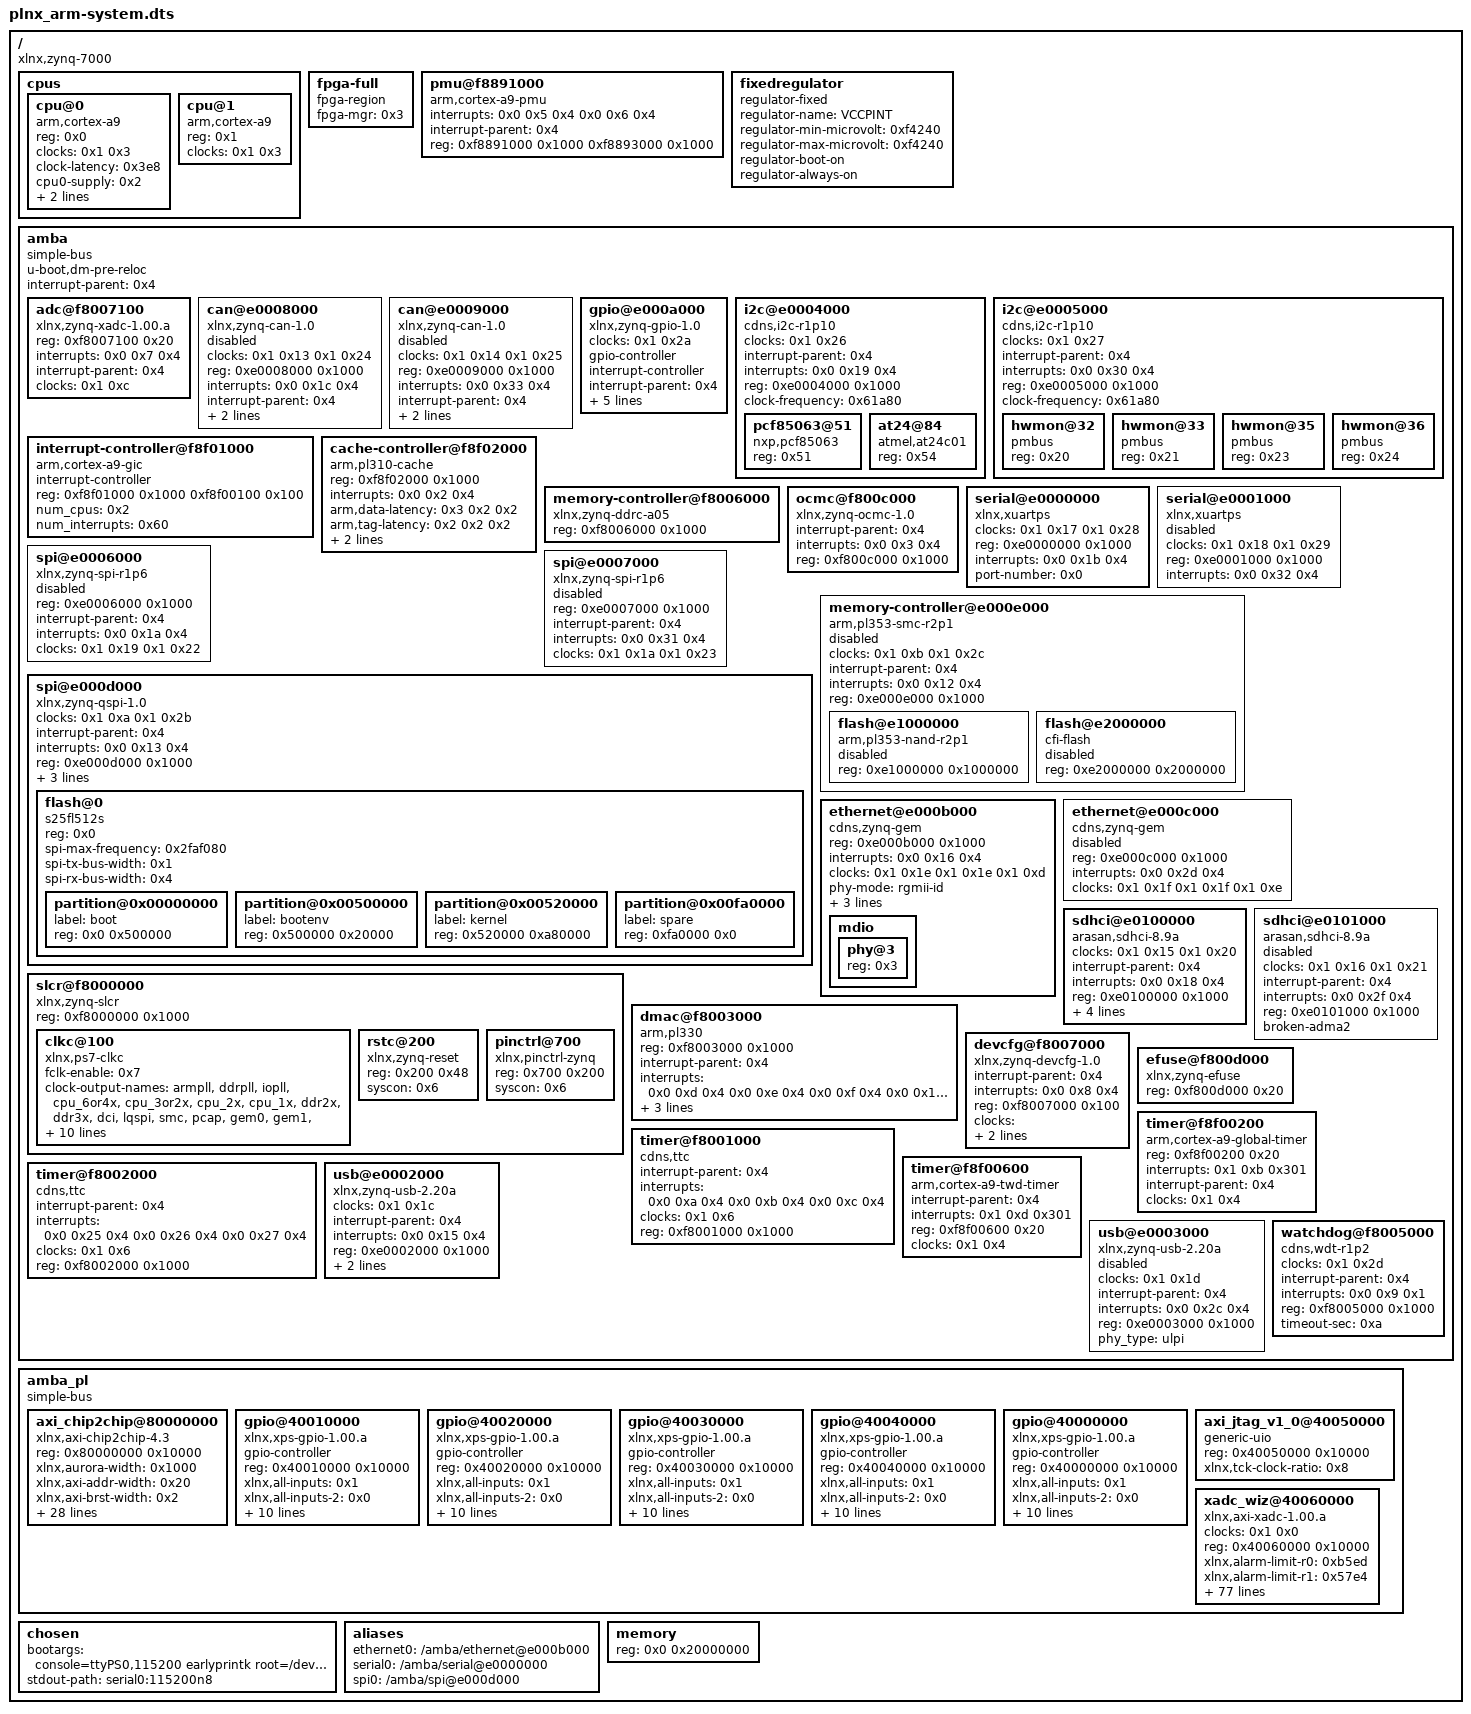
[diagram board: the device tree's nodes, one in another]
/dts-v1/;

/ {
	#address-cells = <0x1>;
	#size-cells = <0x1>;
	compatible = "xlnx,zynq-7000";

	cpus {
		#address-cells = <0x1>;
		#size-cells = <0x0>;

		cpu@0 {
			compatible = "arm,cortex-a9";
			device_type = "cpu";
			reg = <0x0>;
			clocks = <0x1 0x3>;
			clock-latency = <0x3e8>;
			cpu0-supply = <0x2>;
			operating-points = <0xa2c2a 0xf4240 0x51615 0xf4240>;
		};

		cpu@1 {
			compatible = "arm,cortex-a9";
			device_type = "cpu";
			reg = <0x1>;
			clocks = <0x1 0x3>;
		};
	};

	fpga-full {
		compatible = "fpga-region";
		fpga-mgr = <0x3>;
		#address-cells = <0x1>;
		#size-cells = <0x1>;
		ranges;
	};

	pmu@f8891000 {
		compatible = "arm,cortex-a9-pmu";
		interrupts = <0x0 0x5 0x4 0x0 0x6 0x4>;
		interrupt-parent = <0x4>;
		reg = <0xf8891000 0x1000 0xf8893000 0x1000>;
	};

	fixedregulator {
		compatible = "regulator-fixed";
		regulator-name = "VCCPINT";
		regulator-min-microvolt = <0xf4240>;
		regulator-max-microvolt = <0xf4240>;
		regulator-boot-on;
		regulator-always-on;
		linux,phandle = <0x2>;
		phandle = <0x2>;
	};

	amba {
		u-boot,dm-pre-reloc;
		compatible = "simple-bus";
		#address-cells = <0x1>;
		#size-cells = <0x1>;
		interrupt-parent = <0x4>;
		ranges;

		adc@f8007100 {
			compatible = "xlnx,zynq-xadc-1.00.a";
			reg = <0xf8007100 0x20>;
			interrupts = <0x0 0x7 0x4>;
			interrupt-parent = <0x4>;
			clocks = <0x1 0xc>;
		};

		can@e0008000 {
			compatible = "xlnx,zynq-can-1.0";
			status = "disabled";
			clocks = <0x1 0x13 0x1 0x24>;
			clock-names = "can_clk", "pclk";
			reg = <0xe0008000 0x1000>;
			interrupts = <0x0 0x1c 0x4>;
			interrupt-parent = <0x4>;
			tx-fifo-depth = <0x40>;
			rx-fifo-depth = <0x40>;
		};

		can@e0009000 {
			compatible = "xlnx,zynq-can-1.0";
			status = "disabled";
			clocks = <0x1 0x14 0x1 0x25>;
			clock-names = "can_clk", "pclk";
			reg = <0xe0009000 0x1000>;
			interrupts = <0x0 0x33 0x4>;
			interrupt-parent = <0x4>;
			tx-fifo-depth = <0x40>;
			rx-fifo-depth = <0x40>;
		};

		gpio@e000a000 {
			compatible = "xlnx,zynq-gpio-1.0";
			#gpio-cells = <0x2>;
			clocks = <0x1 0x2a>;
			gpio-controller;
			interrupt-controller;
			#interrupt-cells = <0x2>;
			interrupt-parent = <0x4>;
			interrupts = <0x0 0x14 0x4>;
			reg = <0xe000a000 0x1000>;
			emio-gpio-width = <0x40>;
			gpio-mask-high = <0x0>;
			gpio-mask-low = <0x5600>;
		};

		i2c@e0004000 {
			compatible = "cdns,i2c-r1p10";
			status = "okay";
			clocks = <0x1 0x26>;
			interrupt-parent = <0x4>;
			interrupts = <0x0 0x19 0x4>;
			reg = <0xe0004000 0x1000>;
			#address-cells = <0x1>;
			#size-cells = <0x0>;
			clock-frequency = <0x61a80>;

			pcf85063@51 {
				status = "okay";
				compatible = "nxp,pcf85063";
				reg = <0x51>;
			};

			at24@84 {
				status = "okay";
				compatible = "atmel,at24c01";
				reg = <0x54>;
			};
		};

		i2c@e0005000 {
			compatible = "cdns,i2c-r1p10";
			status = "okay";
			clocks = <0x1 0x27>;
			interrupt-parent = <0x4>;
			interrupts = <0x0 0x30 0x4>;
			reg = <0xe0005000 0x1000>;
			#address-cells = <0x1>;
			#size-cells = <0x0>;
			clock-frequency = <0x61a80>;

			hwmon@32 {
				status = "okay";
				compatible = "pmbus";
				reg = <0x20>;
			};

			hwmon@33 {
				status = "okay";
				compatible = "pmbus";
				reg = <0x21>;
			};

			hwmon@35 {
				status = "okay";
				compatible = "pmbus";
				reg = <0x23>;
			};

			hwmon@36 {
				status = "okay";
				compatible = "pmbus";
				reg = <0x24>;
			};
		};

		interrupt-controller@f8f01000 {
			compatible = "arm,cortex-a9-gic";
			#interrupt-cells = <0x3>;
			interrupt-controller;
			reg = <0xf8f01000 0x1000 0xf8f00100 0x100>;
			num_cpus = <0x2>;
			num_interrupts = <0x60>;
			linux,phandle = <0x4>;
			phandle = <0x4>;
		};

		cache-controller@f8f02000 {
			compatible = "arm,pl310-cache";
			reg = <0xf8f02000 0x1000>;
			interrupts = <0x0 0x2 0x4>;
			arm,data-latency = <0x3 0x2 0x2>;
			arm,tag-latency = <0x2 0x2 0x2>;
			cache-unified;
			cache-level = <0x2>;
		};

		memory-controller@f8006000 {
			compatible = "xlnx,zynq-ddrc-a05";
			reg = <0xf8006000 0x1000>;
		};

		ocmc@f800c000 {
			compatible = "xlnx,zynq-ocmc-1.0";
			interrupt-parent = <0x4>;
			interrupts = <0x0 0x3 0x4>;
			reg = <0xf800c000 0x1000>;
		};

		serial@e0000000 {
			compatible = "xlnx,xuartps", "cdns,uart-r1p8";
			status = "okay";
			clocks = <0x1 0x17 0x1 0x28>;
			clock-names = "uart_clk", "pclk";
			reg = <0xe0000000 0x1000>;
			interrupts = <0x0 0x1b 0x4>;
			device_type = "serial";
			port-number = <0x0>;
		};

		serial@e0001000 {
			compatible = "xlnx,xuartps", "cdns,uart-r1p8";
			status = "disabled";
			clocks = <0x1 0x18 0x1 0x29>;
			clock-names = "uart_clk", "pclk";
			reg = <0xe0001000 0x1000>;
			interrupts = <0x0 0x32 0x4>;
		};

		spi@e0006000 {
			compatible = "xlnx,zynq-spi-r1p6";
			reg = <0xe0006000 0x1000>;
			status = "disabled";
			interrupt-parent = <0x4>;
			interrupts = <0x0 0x1a 0x4>;
			clocks = <0x1 0x19 0x1 0x22>;
			clock-names = "ref_clk", "pclk";
			#address-cells = <0x1>;
			#size-cells = <0x0>;
		};

		spi@e0007000 {
			compatible = "xlnx,zynq-spi-r1p6";
			reg = <0xe0007000 0x1000>;
			status = "disabled";
			interrupt-parent = <0x4>;
			interrupts = <0x0 0x31 0x4>;
			clocks = <0x1 0x1a 0x1 0x23>;
			clock-names = "ref_clk", "pclk";
			#address-cells = <0x1>;
			#size-cells = <0x0>;
		};

		spi@e000d000 {
			clock-names = "ref_clk", "pclk";
			clocks = <0x1 0xa 0x1 0x2b>;
			compatible = "xlnx,zynq-qspi-1.0";
			status = "okay";
			interrupt-parent = <0x4>;
			interrupts = <0x0 0x13 0x4>;
			reg = <0xe000d000 0x1000>;
			#address-cells = <0x1>;
			#size-cells = <0x0>;
			is-dual = <0x0>;
			num-cs = <0x1>;
			u-boot,dm-pre-reloc;

			flash@0 {
				compatible = "s25fl512s";
				reg = <0x0>;
				#address-cells = <0x1>;
				#size-cells = <0x1>;
				spi-max-frequency = <0x2faf080>;
				spi-tx-bus-width = <0x1>;
				spi-rx-bus-width = <0x4>;

				partition@0x00000000 {
					label = "boot";
					reg = <0x0 0x500000>;
				};

				partition@0x00500000 {
					label = "bootenv";
					reg = <0x500000 0x20000>;
				};

				partition@0x00520000 {
					label = "kernel";
					reg = <0x520000 0xa80000>;
				};

				partition@0x00fa0000 {
					label = "spare";
					reg = <0xfa0000 0x0>;
				};
			};
		};

		memory-controller@e000e000 {
			#address-cells = <0x1>;
			#size-cells = <0x1>;
			status = "disabled";
			clock-names = "memclk", "aclk";
			clocks = <0x1 0xb 0x1 0x2c>;
			compatible = "arm,pl353-smc-r2p1";
			interrupt-parent = <0x4>;
			interrupts = <0x0 0x12 0x4>;
			ranges;
			reg = <0xe000e000 0x1000>;

			flash@e1000000 {
				status = "disabled";
				compatible = "arm,pl353-nand-r2p1";
				reg = <0xe1000000 0x1000000>;
				#address-cells = <0x1>;
				#size-cells = <0x1>;
			};

			flash@e2000000 {
				status = "disabled";
				compatible = "cfi-flash";
				reg = <0xe2000000 0x2000000>;
				#address-cells = <0x1>;
				#size-cells = <0x1>;
			};
		};

		ethernet@e000b000 {
			compatible = "cdns,zynq-gem", "cdns,gem";
			reg = <0xe000b000 0x1000>;
			status = "okay";
			interrupts = <0x0 0x16 0x4>;
			clocks = <0x1 0x1e 0x1 0x1e 0x1 0xd>;
			clock-names = "pclk", "hclk", "tx_clk";
			#address-cells = <0x1>;
			#size-cells = <0x0>;
			phy-mode = "rgmii-id";
			xlnx,ptp-enet-clock = <0x69f6bcb>;
			local-mac-address = [00 0a 35 00 1e 53];
			phy-handle = <0x5>;

			mdio {

				phy@3 {
					device_type = "ethernet-phy";
					reg = <0x3>;
					linux,phandle = <0x5>;
					phandle = <0x5>;
				};
			};
		};

		ethernet@e000c000 {
			compatible = "cdns,zynq-gem", "cdns,gem";
			reg = <0xe000c000 0x1000>;
			status = "disabled";
			interrupts = <0x0 0x2d 0x4>;
			clocks = <0x1 0x1f 0x1 0x1f 0x1 0xe>;
			clock-names = "pclk", "hclk", "tx_clk";
			#address-cells = <0x1>;
			#size-cells = <0x0>;
		};

		sdhci@e0100000 {
			compatible = "arasan,sdhci-8.9a";
			status = "okay";
			clock-names = "clk_xin", "clk_ahb";
			clocks = <0x1 0x15 0x1 0x20>;
			interrupt-parent = <0x4>;
			interrupts = <0x0 0x18 0x4>;
			reg = <0xe0100000 0x1000>;
			broken-adma2;
			xlnx,has-cd = <0x1>;
			xlnx,has-power = <0x0>;
			xlnx,has-wp = <0x0>;
		};

		sdhci@e0101000 {
			compatible = "arasan,sdhci-8.9a";
			status = "disabled";
			clock-names = "clk_xin", "clk_ahb";
			clocks = <0x1 0x16 0x1 0x21>;
			interrupt-parent = <0x4>;
			interrupts = <0x0 0x2f 0x4>;
			reg = <0xe0101000 0x1000>;
			broken-adma2;
		};

		slcr@f8000000 {
			#address-cells = <0x1>;
			#size-cells = <0x1>;
			compatible = "xlnx,zynq-slcr", "syscon", "simple-mfd";
			reg = <0xf8000000 0x1000>;
			ranges;
			linux,phandle = <0x6>;
			phandle = <0x6>;

			clkc@100 {
				#clock-cells = <0x1>;
				compatible = "xlnx,ps7-clkc";
				fclk-enable = <0x7>;
				clock-output-names = "armpll", "ddrpll", "iopll", "cpu_6or4x", "cpu_3or2x", "cpu_2x", "cpu_1x", "ddr2x", "ddr3x", "dci", "lqspi", "smc", "pcap", "gem0", "gem1", "fclk0", "fclk1", "fclk2", "fclk3", "can0", "can1", "sdio0", "sdio1", "uart0", "uart1", "spi0", "spi1", "dma", "usb0_aper", "usb1_aper", "gem0_aper", "gem1_aper", "sdio0_aper", "sdio1_aper", "spi0_aper", "spi1_aper", "can0_aper", "can1_aper", "i2c0_aper", "i2c1_aper", "uart0_aper", "uart1_aper", "gpio_aper", "lqspi_aper", "smc_aper", "swdt", "dbg_trc", "dbg_apb";
				reg = <0x100 0x100>;
				ps-clk-frequency = <0x1fca055>;
				linux,phandle = <0x1>;
				phandle = <0x1>;
			};

			rstc@200 {
				compatible = "xlnx,zynq-reset";
				reg = <0x200 0x48>;
				#reset-cells = <0x1>;
				syscon = <0x6>;
			};

			pinctrl@700 {
				compatible = "xlnx,pinctrl-zynq";
				reg = <0x700 0x200>;
				syscon = <0x6>;
			};
		};

		dmac@f8003000 {
			compatible = "arm,pl330", "arm,primecell";
			reg = <0xf8003000 0x1000>;
			interrupt-parent = <0x4>;
			interrupt-names = "abort", "dma0", "dma1", "dma2", "dma3", "dma4", "dma5", "dma6", "dma7";
			interrupts = <0x0 0xd 0x4 0x0 0xe 0x4 0x0 0xf 0x4 0x0 0x10 0x4 0x0 0x11 0x4 0x0 0x28 0x4 0x0 0x29 0x4 0x0 0x2a 0x4 0x0 0x2b 0x4>;
			#dma-cells = <0x1>;
			#dma-channels = <0x8>;
			#dma-requests = <0x4>;
			clocks = <0x1 0x1b>;
			clock-names = "apb_pclk";
		};

		devcfg@f8007000 {
			compatible = "xlnx,zynq-devcfg-1.0";
			interrupt-parent = <0x4>;
			interrupts = <0x0 0x8 0x4>;
			reg = <0xf8007000 0x100>;
			clocks = <0x1 0xc 0x1 0xf 0x1 0x10 0x1 0x11 0x1 0x12>;
			clock-names = "ref_clk", "fclk0", "fclk1", "fclk2", "fclk3";
			syscon = <0x6>;
			linux,phandle = <0x3>;
			phandle = <0x3>;
		};

		efuse@f800d000 {
			compatible = "xlnx,zynq-efuse";
			reg = <0xf800d000 0x20>;
		};

		timer@f8f00200 {
			compatible = "arm,cortex-a9-global-timer";
			reg = <0xf8f00200 0x20>;
			interrupts = <0x1 0xb 0x301>;
			interrupt-parent = <0x4>;
			clocks = <0x1 0x4>;
		};

		timer@f8001000 {
			interrupt-parent = <0x4>;
			interrupts = <0x0 0xa 0x4 0x0 0xb 0x4 0x0 0xc 0x4>;
			compatible = "cdns,ttc";
			clocks = <0x1 0x6>;
			reg = <0xf8001000 0x1000>;
		};

		timer@f8002000 {
			interrupt-parent = <0x4>;
			interrupts = <0x0 0x25 0x4 0x0 0x26 0x4 0x0 0x27 0x4>;
			compatible = "cdns,ttc";
			clocks = <0x1 0x6>;
			reg = <0xf8002000 0x1000>;
		};

		timer@f8f00600 {
			interrupt-parent = <0x4>;
			interrupts = <0x1 0xd 0x301>;
			compatible = "arm,cortex-a9-twd-timer";
			reg = <0xf8f00600 0x20>;
			clocks = <0x1 0x4>;
		};

		usb@e0002000 {
			compatible = "xlnx,zynq-usb-2.20a", "chipidea,usb2";
			status = "okay";
			clocks = <0x1 0x1c>;
			interrupt-parent = <0x4>;
			interrupts = <0x0 0x15 0x4>;
			reg = <0xe0002000 0x1000>;
			phy_type = "ulpi";
			dr_mode = "host";
		};

		usb@e0003000 {
			compatible = "xlnx,zynq-usb-2.20a", "chipidea,usb2";
			status = "disabled";
			clocks = <0x1 0x1d>;
			interrupt-parent = <0x4>;
			interrupts = <0x0 0x2c 0x4>;
			reg = <0xe0003000 0x1000>;
			phy_type = "ulpi";
		};

		watchdog@f8005000 {
			clocks = <0x1 0x2d>;
			compatible = "cdns,wdt-r1p2";
			interrupt-parent = <0x4>;
			interrupts = <0x0 0x9 0x1>;
			reg = <0xf8005000 0x1000>;
			timeout-sec = <0xa>;
		};
	};

	amba_pl {
		#address-cells = <0x1>;
		#size-cells = <0x1>;
		compatible = "simple-bus";
		ranges;

		axi_chip2chip@80000000 {
			compatible = "xlnx,axi-chip2chip-4.3";
			reg = <0x80000000 0x10000>;
			xlnx,aurora-width = <0x1000>;
			xlnx,axi-addr-width = <0x20>;
			xlnx,axi-brst-width = <0x2>;
			xlnx,axi-bus-type = <0x0>;
			xlnx,axi-data-width = <0x20>;
			xlnx,axi-id-width = <0xc>;
			xlnx,axi-len-width = <0x8>;
			xlnx,axi-lite-addr-width = <0x20>;
			xlnx,axi-lite-data-width = <0x20>;
			xlnx,axi-lite-prot-width = <0x2>;
			xlnx,axi-lite-resp-width = <0x2>;
			xlnx,axi-lite-stb-width = <0x4>;
			xlnx,axi-resp-width = <0x2>;
			xlnx,axi-size-width = <0x3>;
			xlnx,axi-stb-width = <0x4>;
			xlnx,axi-wuser-width = <0x1>;
			xlnx,common-clk = <0x1>;
			xlnx,disable-clk-shift = <0x0>;
			xlnx,disable-deskew = <0x0>;
			xlnx,ecc-enable = <0x1>;
			xlnx,include-axilite = <0x0>;
			xlnx,interface-mode = <0x2>;
			xlnx,interface-type = <0x1>;
			xlnx,interrupt-width = <0x4>;
			xlnx,master-fpga = <0x1>;
			xlnx,num-of-io = <0x16>;
			xlnx,selectio-phy-clk = <0x64>;
			xlnx,simulation = <0x0>;
			xlnx,support-narrowburst = "axi_c2c";
			xlnx,use-diff-clk = <0x1>;
			xlnx,use-diff-io = <0x0>;
		};

		gpio@40010000 {
			#gpio-cells = <0x2>;
			compatible = "xlnx,xps-gpio-1.00.a";
			gpio-controller;
			reg = <0x40010000 0x10000>;
			xlnx,all-inputs = <0x1>;
			xlnx,all-inputs-2 = <0x0>;
			xlnx,all-outputs = <0x0>;
			xlnx,all-outputs-2 = <0x1>;
			xlnx,dout-default = <0x0>;
			xlnx,dout-default-2 = <0x0>;
			xlnx,gpio-width = <0x8>;
			xlnx,gpio2-width = <0x16>;
			xlnx,interrupt-present = <0x0>;
			xlnx,is-dual = <0x1>;
			xlnx,tri-default = <0xffffffff>;
			xlnx,tri-default-2 = <0xffffffff>;
		};

		gpio@40020000 {
			#gpio-cells = <0x2>;
			compatible = "xlnx,xps-gpio-1.00.a";
			gpio-controller;
			reg = <0x40020000 0x10000>;
			xlnx,all-inputs = <0x1>;
			xlnx,all-inputs-2 = <0x0>;
			xlnx,all-outputs = <0x0>;
			xlnx,all-outputs-2 = <0x1>;
			xlnx,dout-default = <0x0>;
			xlnx,dout-default-2 = <0x0>;
			xlnx,gpio-width = <0xa>;
			xlnx,gpio2-width = <0x6>;
			xlnx,interrupt-present = <0x0>;
			xlnx,is-dual = <0x1>;
			xlnx,tri-default = <0xffffffff>;
			xlnx,tri-default-2 = <0xffffffff>;
		};

		gpio@40030000 {
			#gpio-cells = <0x2>;
			compatible = "xlnx,xps-gpio-1.00.a";
			gpio-controller;
			reg = <0x40030000 0x10000>;
			xlnx,all-inputs = <0x1>;
			xlnx,all-inputs-2 = <0x0>;
			xlnx,all-outputs = <0x0>;
			xlnx,all-outputs-2 = <0x1>;
			xlnx,dout-default = <0x0>;
			xlnx,dout-default-2 = <0x0>;
			xlnx,gpio-width = <0x3>;
			xlnx,gpio2-width = <0x3>;
			xlnx,interrupt-present = <0x0>;
			xlnx,is-dual = <0x1>;
			xlnx,tri-default = <0xffffffff>;
			xlnx,tri-default-2 = <0xffffffff>;
		};

		gpio@40040000 {
			#gpio-cells = <0x2>;
			compatible = "xlnx,xps-gpio-1.00.a";
			gpio-controller;
			reg = <0x40040000 0x10000>;
			xlnx,all-inputs = <0x1>;
			xlnx,all-inputs-2 = <0x0>;
			xlnx,all-outputs = <0x0>;
			xlnx,all-outputs-2 = <0x1>;
			xlnx,dout-default = <0x0>;
			xlnx,dout-default-2 = <0x0>;
			xlnx,gpio-width = <0x3>;
			xlnx,gpio2-width = <0x2>;
			xlnx,interrupt-present = <0x0>;
			xlnx,is-dual = <0x1>;
			xlnx,tri-default = <0xffffffff>;
			xlnx,tri-default-2 = <0xffffffff>;
		};

		gpio@40000000 {
			#gpio-cells = <0x2>;
			compatible = "xlnx,xps-gpio-1.00.a";
			gpio-controller;
			reg = <0x40000000 0x10000>;
			xlnx,all-inputs = <0x1>;
			xlnx,all-inputs-2 = <0x0>;
			xlnx,all-outputs = <0x0>;
			xlnx,all-outputs-2 = <0x1>;
			xlnx,dout-default = <0x0>;
			xlnx,dout-default-2 = <0x0>;
			xlnx,gpio-width = <0x10>;
			xlnx,gpio2-width = <0x9>;
			xlnx,interrupt-present = <0x0>;
			xlnx,is-dual = <0x1>;
			xlnx,tri-default = <0xffffffff>;
			xlnx,tri-default-2 = <0xffffffff>;
		};

		axi_jtag_v1_0@40050000 {
			compatible = "generic-uio";
			reg = <0x40050000 0x10000>;
			xlnx,tck-clock-ratio = <0x8>;
		};

		xadc_wiz@40060000 {
			clock-names = "ref_clk";
			clocks = <0x1 0x0>;
			compatible = "xlnx,axi-xadc-1.00.a";
			reg = <0x40060000 0x10000>;
			xlnx,alarm-limit-r0 = <0xb5ed>;
			xlnx,alarm-limit-r1 = <0x57e4>;
			xlnx,alarm-limit-r10 = <0x5555>;
			xlnx,alarm-limit-r11 = <0x5111>;
			xlnx,alarm-limit-r12 = <0x9999>;
			xlnx,alarm-limit-r13 = <0x91eb>;
			xlnx,alarm-limit-r14 = <0x6aaa>;
			xlnx,alarm-limit-r15 = <0x6666>;
			xlnx,alarm-limit-r2 = <0xa147>;
			xlnx,alarm-limit-r3 = <0xb5e3>;
			xlnx,alarm-limit-r4 = <0xa93a>;
			xlnx,alarm-limit-r5 = <0x52c6>;
			xlnx,alarm-limit-r6 = <0x9555>;
			xlnx,alarm-limit-r7 = <0xae4e>;
			xlnx,alarm-limit-r8 = <0x5999>;
			xlnx,alarm-limit-r9 = <0x5111>;
			xlnx,configuration-r0 = <0x0>;
			xlnx,configuration-r1 = <0x31a0>;
			xlnx,configuration-r2 = <0x400>;
			xlnx,dclk-frequency = <0x64>;
			xlnx,external-mux = "none";
			xlnx,external-mux-channel = "VP_VN";
			xlnx,external-muxaddr-enable = <0x0>;
			xlnx,fifo-depth = <0x7>;
			xlnx,has-axi = <0x1>;
			xlnx,has-axi4stream = <0x0>;
			xlnx,has-busy = <0x1>;
			xlnx,has-channel = <0x1>;
			xlnx,has-convst = <0x0>;
			xlnx,has-convstclk = <0x0>;
			xlnx,has-dclk = <0x1>;
			xlnx,has-drp = <0x0>;
			xlnx,has-eoc = <0x1>;
			xlnx,has-eos = <0x1>;
			xlnx,has-external-mux = <0x0>;
			xlnx,has-jtagbusy = <0x0>;
			xlnx,has-jtaglocked = <0x0>;
			xlnx,has-jtagmodified = <0x0>;
			xlnx,has-ot-alarm = <0x1>;
			xlnx,has-reset = <0x0>;
			xlnx,has-temp-bus = <0x0>;
			xlnx,has-user-temp-alarm = <0x1>;
			xlnx,has-vbram-alarm = <0x0>;
			xlnx,has-vccaux-alarm = <0x1>;
			xlnx,has-vccddro-alarm = <0x1>;
			xlnx,has-vccint-alarm = <0x1>;
			xlnx,has-vccpaux-alarm = <0x1>;
			xlnx,has-vccpint-alarm = <0x1>;
			xlnx,has-vn = <0x1>;
			xlnx,has-vp = <0x1>;
			xlnx,include-intr = <0x1>;
			xlnx,sampling-rate = "961538.4615384615";
			xlnx,sequence-r0 = <0x100>;
			xlnx,sequence-r1 = <0x0>;
			xlnx,sequence-r2 = <0x0>;
			xlnx,sequence-r3 = <0x0>;
			xlnx,sequence-r4 = <0x0>;
			xlnx,sequence-r5 = <0x0>;
			xlnx,sequence-r6 = <0x0>;
			xlnx,sequence-r7 = <0x0>;
			xlnx,sim-file-name = "design";
			xlnx,sim-file-rel-path = "./";
			xlnx,sim-file-sel = "Default";
			xlnx,vaux0 = <0x0>;
			xlnx,vaux1 = <0x0>;
			xlnx,vaux10 = <0x0>;
			xlnx,vaux11 = <0x0>;
			xlnx,vaux12 = <0x0>;
			xlnx,vaux13 = <0x0>;
			xlnx,vaux14 = <0x0>;
			xlnx,vaux15 = <0x0>;
			xlnx,vaux2 = <0x0>;
			xlnx,vaux3 = <0x0>;
			xlnx,vaux4 = <0x0>;
			xlnx,vaux5 = <0x0>;
			xlnx,vaux6 = <0x0>;
			xlnx,vaux7 = <0x0>;
			xlnx,vaux8 = <0x0>;
			xlnx,vaux9 = <0x0>;
		};
	};

	chosen {
		bootargs = "console=ttyPS0,115200 earlyprintk root=/dev/mmcblk0p2 rw rootwait uio_pdrv_genirq.of_id=\"generic-uio\"";
		stdout-path = "serial0:115200n8";
	};

	aliases {
		ethernet0 = "/amba/ethernet@e000b000";
		serial0 = "/amba/serial@e0000000";
		spi0 = "/amba/spi@e000d000";
	};

	memory {
		device_type = "memory";
		reg = <0x0 0x20000000>;
	};
};
